# STC32G144K246 register map
Vendor: STC; File version: 2.0
Registers are 8-bit, read-write, no defined reset value unless marked. A register's access mark holds for its fields unless they carry their own. Offsets are from the block's base; [hi:lo] are bit positions; {n}, {i} and the like mark numbered series.

## GPIO5 — P5 端口、模式、上下拉和中断
Base 0x007EFD05
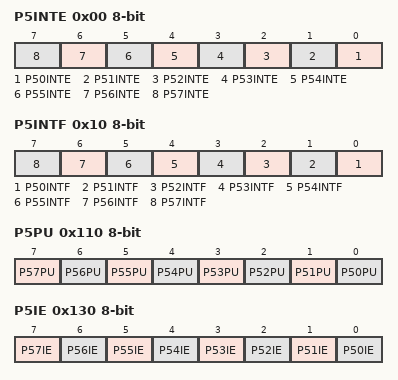
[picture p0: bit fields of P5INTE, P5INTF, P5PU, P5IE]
0x00 P5INTE — P5口中断使能寄存器
  [n-50] P{n}INTE (n=50..57) — 尚未自动匹配到此字段的独立说明；请查看下方章节说明。
0x10 P5INTF ro — P5口中断标志寄存器
  [n-50] P{n}INTF (n=50..57) — 尚未自动匹配到此字段的独立说明；请查看下方章节说明。
0x110 P5PU — P5口上拉电阻控制寄存器
  [all] fields
    0=禁止内部上拉电阻; 1=使能内部上拉电阻
  [7] P57PU — 控制 P5.7 的内部上拉电阻。
  [6] P56PU — 控制 P5.6 的内部上拉电阻。
  [5] P55PU — 控制 P5.5 的内部上拉电阻。
  [4] P54PU — 控制 P5.4 的内部上拉电阻。
  [3] P53PU — 控制 P5.3 的内部上拉电阻。
  [2] P52PU — 控制 P5.2 的内部上拉电阻。
  [1] P51PU — 控制 P5.1 的内部上拉电阻。
  [0] P50PU — 控制 P5.0 的内部上拉电阻。
0x130 P5IE — P5口输入使能控制寄存器
  [all] fields
    0=禁止数字信号输入，用于模拟功能; 1=使能数字信号输入
  [7] P57IE — 控制 P5.7 的数字信号输入。
  [6] P56IE — 控制 P5.6 的数字信号输入。
  [5] P55IE — 控制 P5.5 的数字信号输入。
  [4] P54IE — 控制 P5.4 的数字信号输入。
  [3] P53IE — 控制 P5.3 的数字信号输入。
  [2] P52IE — 控制 P5.2 的数字信号输入。
  [1] P51IE — 控制 P5.1 的数字信号输入。
  [0] P50IE — 控制 P5.0 的数字信号输入。
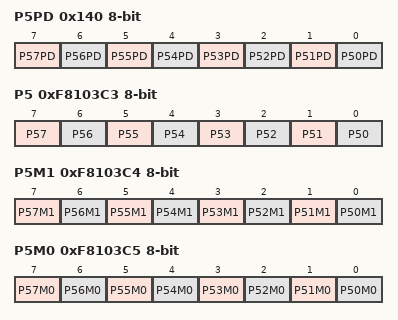
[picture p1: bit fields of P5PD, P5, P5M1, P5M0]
0x140 P5PD — P5口下拉电阻控制寄存器
  [all] fields
    0=禁止内部下拉电阻; 1=使能内部下拉电阻
  [7] P57PD — 控制 P5.7 的内部下拉电阻。
  [6] P56PD — 控制 P5.6 的内部下拉电阻。
  [5] P55PD — 控制 P5.5 的内部下拉电阻。
  [4] P54PD — 控制 P5.4 的内部下拉电阻。
  [3] P53PD — 控制 P5.3 的内部下拉电阻。
  [2] P52PD — 控制 P5.2 的内部下拉电阻。
  [1] P51PD — 控制 P5.1 的内部下拉电阻。
  [0] P50PD — 控制 P5.0 的内部下拉电阻。
0xF8103C3 P5 — P5端口
  [all] fields
    0=低电平; 1=高电平
  [7] P57 — 读取 P5.7 管脚电平；写入 P5.7 的输出缓冲区。实际输出行为由端口模式及外设复用共同决定。
  [6] P56 — 读取 P5.6 管脚电平；写入 P5.6 的输出缓冲区。实际输出行为由端口模式及外设复用共同决定。
  [5] P55 — 读取 P5.5 管脚电平；写入 P5.5 的输出缓冲区。实际输出行为由端口模式及外设复用共同决定。
  [4] P54 — 读取 P5.4 管脚电平；写入 P5.4 的输出缓冲区。实际输出行为由端口模式及外设复用共同决定。
  [3] P53 — 读取 P5.3 管脚电平；写入 P5.3 的输出缓冲区。实际输出行为由端口模式及外设复用共同决定。
  [2] P52 — 读取 P5.2 管脚电平；写入 P5.2 的输出缓冲区。实际输出行为由端口模式及外设复用共同决定。
  [1] P51 — 读取 P5.1 管脚电平；写入 P5.1 的输出缓冲区。实际输出行为由端口模式及外设复用共同决定。
  [0] P50 — 读取 P5.0 管脚电平；写入 P5.0 的输出缓冲区。实际输出行为由端口模式及外设复用共同决定。
0xF8103C4 P5M1 — P5口配置寄存器1
  [7] P57M1 — 控制 P5.7 的端口模式高位；与 P5M0.B7 配合设置，组合含义见下表。
  [6] P56M1 — 控制 P5.6 的端口模式高位；与 P5M0.B6 配合设置，组合含义见下表。
  [5] P55M1 — 控制 P5.5 的端口模式高位；与 P5M0.B5 配合设置，组合含义见下表。
  [4] P54M1 — 控制 P5.4 的端口模式高位；与 P5M0.B4 配合设置，组合含义见下表。
  [3] P53M1 — 控制 P5.3 的端口模式高位；与 P5M0.B3 配合设置，组合含义见下表。
  [2] P52M1 — 控制 P5.2 的端口模式高位；与 P5M0.B2 配合设置，组合含义见下表。
  [1] P51M1 — 控制 P5.1 的端口模式高位；与 P5M0.B1 配合设置，组合含义见下表。
  [0] P50M1 — 控制 P5.0 的端口模式高位；与 P5M0.B0 配合设置，组合含义见下表。
0xF8103C5 P5M0 — P5口配置寄存器0
  [7] P57M0 — 控制 P5.7 的端口模式低位；与 P5M1.B7 配合设置，组合含义见下表。
  [6] P56M0 — 控制 P5.6 的端口模式低位；与 P5M1.B6 配合设置，组合含义见下表。
  [5] P55M0 — 控制 P5.5 的端口模式低位；与 P5M1.B5 配合设置，组合含义见下表。
  [4] P54M0 — 控制 P5.4 的端口模式低位；与 P5M1.B4 配合设置，组合含义见下表。
  [3] P53M0 — 控制 P5.3 的端口模式低位；与 P5M1.B3 配合设置，组合含义见下表。
  [2] P52M0 — 控制 P5.2 的端口模式低位；与 P5M1.B2 配合设置，组合含义见下表。
  [1] P51M0 — 控制 P5.1 的端口模式低位；与 P5M1.B1 配合设置，组合含义见下表。
  [0] P50M0 — 控制 P5.0 的端口模式低位；与 P5M1.B0 配合设置，组合含义见下表。

## GPIO6 — P6 端口、模式、上下拉和中断
Base 0x007EFD06
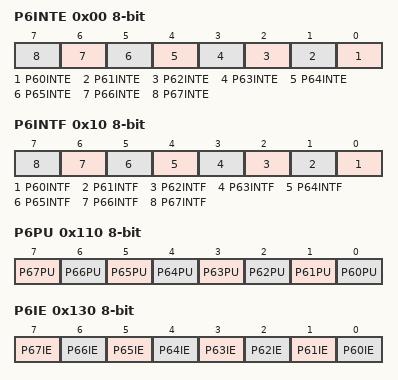
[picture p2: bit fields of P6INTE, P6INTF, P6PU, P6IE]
0x00 P6INTE — P6口中断使能寄存器
  [n-60] P{n}INTE (n=60..67) — 尚未自动匹配到此字段的独立说明；请查看下方章节说明。
0x10 P6INTF ro — P6口中断标志寄存器
  [n-60] P{n}INTF (n=60..67) — 尚未自动匹配到此字段的独立说明；请查看下方章节说明。
0x110 P6PU — P6口上拉电阻控制寄存器
  [all] fields
    0=禁止内部上拉电阻; 1=使能内部上拉电阻
  [7] P67PU — 控制 P6.7 的内部上拉电阻。
  [6] P66PU — 控制 P6.6 的内部上拉电阻。
  [5] P65PU — 控制 P6.5 的内部上拉电阻。
  [4] P64PU — 控制 P6.4 的内部上拉电阻。
  [3] P63PU — 控制 P6.3 的内部上拉电阻。
  [2] P62PU — 控制 P6.2 的内部上拉电阻。
  [1] P61PU — 控制 P6.1 的内部上拉电阻。
  [0] P60PU — 控制 P6.0 的内部上拉电阻。
0x130 P6IE — P6口输入使能控制寄存器
  [all] fields
    0=禁止数字信号输入，用于模拟功能; 1=使能数字信号输入
  [7] P67IE — 控制 P6.7 的数字信号输入。
  [6] P66IE — 控制 P6.6 的数字信号输入。
  [5] P65IE — 控制 P6.5 的数字信号输入。
  [4] P64IE — 控制 P6.4 的数字信号输入。
  [3] P63IE — 控制 P6.3 的数字信号输入。
  [2] P62IE — 控制 P6.2 的数字信号输入。
  [1] P61IE — 控制 P6.1 的数字信号输入。
  [0] P60IE — 控制 P6.0 的数字信号输入。
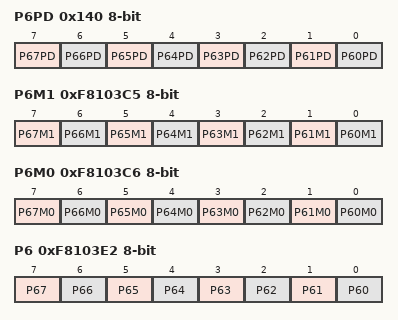
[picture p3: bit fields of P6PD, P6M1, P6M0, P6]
0x140 P6PD — P6口下拉电阻控制寄存器
  [all] fields
    0=禁止内部下拉电阻; 1=使能内部下拉电阻
  [7] P67PD — 控制 P6.7 的内部下拉电阻。
  [6] P66PD — 控制 P6.6 的内部下拉电阻。
  [5] P65PD — 控制 P6.5 的内部下拉电阻。
  [4] P64PD — 控制 P6.4 的内部下拉电阻。
  [3] P63PD — 控制 P6.3 的内部下拉电阻。
  [2] P62PD — 控制 P6.2 的内部下拉电阻。
  [1] P61PD — 控制 P6.1 的内部下拉电阻。
  [0] P60PD — 控制 P6.0 的内部下拉电阻。
0xF8103C5 P6M1 — P6口配置寄存器1
  [7] P67M1 — 控制 P6.7 的端口模式高位；与 P6M0.B7 配合设置，组合含义见下表。
  [6] P66M1 — 控制 P6.6 的端口模式高位；与 P6M0.B6 配合设置，组合含义见下表。
  [5] P65M1 — 控制 P6.5 的端口模式高位；与 P6M0.B5 配合设置，组合含义见下表。
  [4] P64M1 — 控制 P6.4 的端口模式高位；与 P6M0.B4 配合设置，组合含义见下表。
  [3] P63M1 — 控制 P6.3 的端口模式高位；与 P6M0.B3 配合设置，组合含义见下表。
  [2] P62M1 — 控制 P6.2 的端口模式高位；与 P6M0.B2 配合设置，组合含义见下表。
  [1] P61M1 — 控制 P6.1 的端口模式高位；与 P6M0.B1 配合设置，组合含义见下表。
  [0] P60M1 — 控制 P6.0 的端口模式高位；与 P6M0.B0 配合设置，组合含义见下表。
0xF8103C6 P6M0 — P6口配置寄存器0
  [7] P67M0 — 控制 P6.7 的端口模式低位；与 P6M1.B7 配合设置，组合含义见下表。
  [6] P66M0 — 控制 P6.6 的端口模式低位；与 P6M1.B6 配合设置，组合含义见下表。
  [5] P65M0 — 控制 P6.5 的端口模式低位；与 P6M1.B5 配合设置，组合含义见下表。
  [4] P64M0 — 控制 P6.4 的端口模式低位；与 P6M1.B4 配合设置，组合含义见下表。
  [3] P63M0 — 控制 P6.3 的端口模式低位；与 P6M1.B3 配合设置，组合含义见下表。
  [2] P62M0 — 控制 P6.2 的端口模式低位；与 P6M1.B2 配合设置，组合含义见下表。
  [1] P61M0 — 控制 P6.1 的端口模式低位；与 P6M1.B1 配合设置，组合含义见下表。
  [0] P60M0 — 控制 P6.0 的端口模式低位；与 P6M1.B0 配合设置，组合含义见下表。
0xF8103E2 P6 — P6端口
  [all] fields
    0=低电平; 1=高电平
  [7] P67 — 读取 P6.7 管脚电平；写入 P6.7 的输出缓冲区。实际输出行为由端口模式及外设复用共同决定。
  [6] P66 — 读取 P6.6 管脚电平；写入 P6.6 的输出缓冲区。实际输出行为由端口模式及外设复用共同决定。
  [5] P65 — 读取 P6.5 管脚电平；写入 P6.5 的输出缓冲区。实际输出行为由端口模式及外设复用共同决定。
  [4] P64 — 读取 P6.4 管脚电平；写入 P6.4 的输出缓冲区。实际输出行为由端口模式及外设复用共同决定。
  [3] P63 — 读取 P6.3 管脚电平；写入 P6.3 的输出缓冲区。实际输出行为由端口模式及外设复用共同决定。
  [2] P62 — 读取 P6.2 管脚电平；写入 P6.2 的输出缓冲区。实际输出行为由端口模式及外设复用共同决定。
  [1] P61 — 读取 P6.1 管脚电平；写入 P6.1 的输出缓冲区。实际输出行为由端口模式及外设复用共同决定。
  [0] P60 — 读取 P6.0 管脚电平；写入 P6.0 的输出缓冲区。实际输出行为由端口模式及外设复用共同决定。
